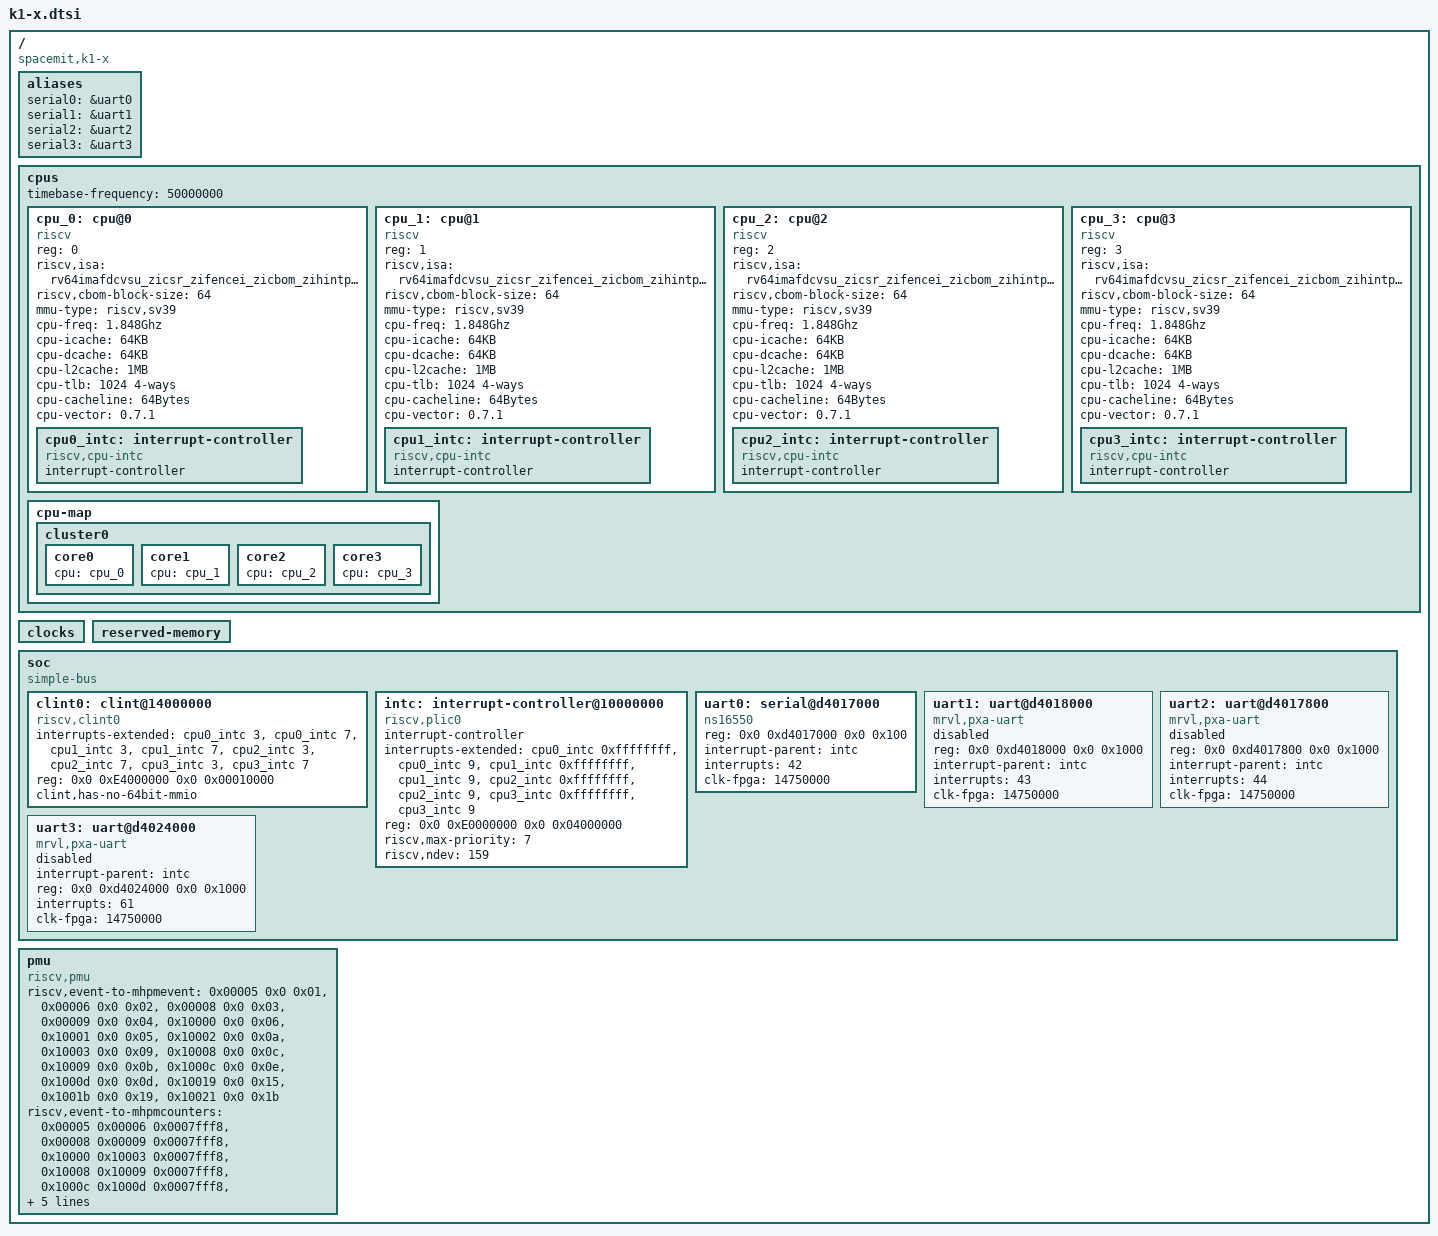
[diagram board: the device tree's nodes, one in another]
// SPDX-License-Identifier: (GPL-2.0 OR MIT)
/* Copyright (c) 2022 Spacemit, Inc */

/dts-v1/;


/ {
	compatible = "spacemit,k1-x", "riscv";
	#address-cells = <2>;
	#size-cells = <2>;

	aliases {
		serial0 = &uart0;
		serial1 = &uart1;
		serial2 = &uart2;
		serial3 = &uart3;
	};

	cpus: cpus {
		#address-cells = <1>;
		#size-cells = <0>;
		timebase-frequency = <50000000>;
		cpu_0: cpu@0 {
			device_type = "cpu";
			reg = <0>;
			status = "okay";
			compatible = "riscv";
			riscv,isa = "rv64imafdcvsu_zicsr_zifencei_zicbom_zihintpause_zba_zbb_zbc_zbs_svpbmt";
			riscv,cbom-block-size = <64>;
			mmu-type = "riscv,sv39";
			cpu-freq = "1.848Ghz";
			cpu-icache = "64KB";
			cpu-dcache = "64KB";
			cpu-l2cache = "1MB";
			cpu-tlb = "1024 4-ways";
			cpu-cacheline = "64Bytes";
			cpu-vector = "0.7.1";

			cpu0_intc: interrupt-controller {
				#interrupt-cells = <1>;
				compatible = "riscv,cpu-intc";
				interrupt-controller;
			};
		};
		cpu_1: cpu@1 {
			device_type = "cpu";
			reg = <1>;
			status = "okay";
			compatible = "riscv";
			riscv,isa = "rv64imafdcvsu_zicsr_zifencei_zicbom_zihintpause_zba_zbb_zbc_zbs_svpbmt";
			riscv,cbom-block-size = <64>;
			mmu-type = "riscv,sv39";
			cpu-freq = "1.848Ghz";
			cpu-icache = "64KB";
			cpu-dcache = "64KB";
			cpu-l2cache = "1MB";
			cpu-tlb = "1024 4-ways";
			cpu-cacheline = "64Bytes";
			cpu-vector = "0.7.1";

			cpu1_intc: interrupt-controller {
				#interrupt-cells = <1>;
				compatible = "riscv,cpu-intc";
				interrupt-controller;
			};
		};
		cpu_2: cpu@2 {
			device_type = "cpu";
			reg = <2>;
			status = "okay";
			compatible = "riscv";
			riscv,isa = "rv64imafdcvsu_zicsr_zifencei_zicbom_zihintpause_zba_zbb_zbc_zbs_svpbmt";
			riscv,cbom-block-size = <64>;
			mmu-type = "riscv,sv39";
			cpu-freq = "1.848Ghz";
			cpu-icache = "64KB";
			cpu-dcache = "64KB";
			cpu-l2cache = "1MB";
			cpu-tlb = "1024 4-ways";
			cpu-cacheline = "64Bytes";
			cpu-vector = "0.7.1";

			cpu2_intc: interrupt-controller {
				#interrupt-cells = <1>;
				compatible = "riscv,cpu-intc";
				interrupt-controller;
			};
		};
		cpu_3: cpu@3 {
			device_type = "cpu";
			reg = <3>;
			status = "okay";
			compatible = "riscv";
			riscv,isa = "rv64imafdcvsu_zicsr_zifencei_zicbom_zihintpause_zba_zbb_zbc_zbs_svpbmt";
			riscv,cbom-block-size = <64>;
			mmu-type = "riscv,sv39";
			cpu-freq = "1.848Ghz";
			cpu-icache = "64KB";
			cpu-dcache = "64KB";
			cpu-l2cache = "1MB";
			cpu-tlb = "1024 4-ways";
			cpu-cacheline = "64Bytes";
			cpu-vector = "0.7.1";

			cpu3_intc: interrupt-controller {
				#interrupt-cells = <1>;
				compatible = "riscv,cpu-intc";
				interrupt-controller;
			};
		};

		cpu-map {
			cluster0 {
				core0 {
					cpu = <&cpu_0>;
				};

				core1 {
					cpu = <&cpu_1>;
				};
				core2 {
					cpu = <&cpu_2>;
				};

				core3 {
					cpu = <&cpu_3>;
				};
			};
		};
	};

	clocks {
		#address-cells = <0x2>;
		#size-cells = <0x2>;
		ranges;
	};

	reserved-memory {
		#address-cells = <2>;
		#size-cells = <2>;
		ranges;
	};

	soc {
		compatible = "simple-bus";
		#address-cells = <2>;
		#size-cells = <2>;
		ranges;

		clint0: clint@14000000 {
			compatible = "riscv,clint0";
			interrupts-extended = <
				&cpu0_intc  3 &cpu0_intc  7
				&cpu1_intc  3 &cpu1_intc  7
				&cpu2_intc  3 &cpu2_intc  7
				&cpu3_intc  3 &cpu3_intc  7
			>;
			reg = <0x0 0xE4000000 0x0 0x00010000>;
			clint,has-no-64bit-mmio;
		};

		intc: interrupt-controller@10000000 {
			#interrupt-cells = <1>;
			compatible = "riscv,plic0";
			interrupt-controller;
			interrupts-extended = <
				&cpu0_intc 0xffffffff &cpu0_intc 9
				&cpu1_intc 0xffffffff &cpu1_intc 9
				&cpu2_intc 0xffffffff &cpu2_intc 9
				&cpu3_intc 0xffffffff &cpu3_intc 9
			>;
			reg = <0x0 0xE0000000 0x0 0x04000000>;
			reg-names = "control";
			riscv,max-priority = <7>;
			riscv,ndev = <159>;
		};

		uart0: serial@d4017000 {
			compatible = "ns16550";
			reg = <0x0 0xd4017000 0x0 0x100>;
			interrupt-parent = <&intc>;
			interrupts = <42>;
			/*
			dmas = <&pdma0 AP_UART1_RX 1
				&pdma0 AP_UART1_TX 1>;
			dma-names = "rx", "tx";
			clocks = <&soc_clocks CLK_UART1>;
			*/
			clk-fpga = <14750000>;
			/*
			lpm-qos = <PM_QOS_CPUIDLE_BLOCK_AXI>;
			edge-wakeup-pin = <54>;
			*/
			status = "ok";
		};

		uart1: uart@d4018000 {
			compatible = "mrvl,pxa-uart";
			reg = <0x0 0xd4018000 0x0 0x1000>;
			interrupt-parent = <&intc>;
			interrupts = <43>;
			/*
			dmas = <&pdma0 AP_UART2_RX 1
				&pdma0 AP_UART2_TX 1>;
			dma-names = "rx", "tx";
			clocks = <&soc_clocks CLK_UART2>;
			*/

			clk-fpga = <14750000>;
			/*
			lpm-qos = <PM_QOS_CPUIDLE_BLOCK_AXI>;
			*/
			status = "disabled";
		};

		uart2: uart@d4017800 {
			compatible = "mrvl,pxa-uart";
			reg = <0x0 0xd4017800 0x0 0x1000>;
			interrupt-parent = <&intc>;
			interrupts = <44>;
			/*
			dmas = <&pdma0 AP_UART3_RX 1
				&pdma0 AP_UART3_TX 1>;
			dma-names = "rx", "tx";
			clocks = <&soc_clocks CLK_UART3>;
			*/
			clk-fpga = <14750000>;
			/*
			lpm-qos = <PM_QOS_CPUIDLE_BLOCK_AXI>;
			*/
			status = "disabled";
		};

		uart3: uart@d4024000 {
			compatible = "mrvl,pxa-uart";
			interrupt-parent = <&intc>;
			reg = <0x0 0xd4024000 0x0 0x1000>;
			interrupts = <61>;
			/*
			dmas = <&pdma0 AP_UART4_RX 1
				&pdma0 AP_UART4_TX 1>;
			dma-names = "rx", "tx";
			clocks = <&soc_clocks CLK_UART4>;
			*/
			clk-fpga = <14750000>;
			/*
			lpm-qos = <PM_QOS_CPUIDLE_BLOCK_AXI>;
			*/
			status = "disabled";
		};
	};

	pmu {
		compatible = "riscv,pmu";

		riscv,event-to-mhpmevent =
			/* BRANCH_INSTRUCTIONS */
			<0x00005 0x0 0x01>,
			/* BRANCH_MISSES */
			<0x00006 0x0 0x02>,
			/* STALLED_CYCLES_FRONTEND */
			<0x00008 0x0 0x03>,
			/* STALLED_CYCLES_BACKEND */
			<0x00009 0x0 0x04>,
			/* L1D_READ_ACCESS */
			<0x10000 0x0 0x06>,
			/* L1D_READ_MISS */
			<0x10001 0x0 0x05>,
			/* L1D_WRITE_ACCESS */
			<0x10002 0x0 0x0a>,
			/* L1D_WRITE_MISS */
			<0x10003 0x0 0x09>,
			/* L1I_READ_ACCESS */
			<0x10008 0x0 0x0c>,
			/* L1I_READ_MISS */
			<0x10009 0x0 0x0b>,
			/* L1I_PREFETCH_ACCESS */
			<0x1000c 0x0 0x0e>,
			/* L1I_PREFETCH_MISS */
			<0x1000d 0x0 0x0d>,
			/* DTLB_READ_MISS */
			<0x10019 0x0 0x15>,
			/* DTLB_WRITE_MISS */
			<0x1001b 0x0 0x19>,
			/* ITLB_READ_MISS */
			<0x10021 0x0 0x1b>;

		/* 16 valid counters: mhpmcounter3 ~ mhpmcounter18 */
		riscv,event-to-mhpmcounters =
			<0x00005 0x00006 0x0007fff8>,
			<0x00008 0x00009 0x0007fff8>,
			<0x10000 0x10003 0x0007fff8>,
			<0x10008 0x10009 0x0007fff8>,
			<0x1000c 0x1000d 0x0007fff8>,
			<0x10019 0x10019 0x0007fff8>,
			<0x1001b 0x1001b 0x0007fff8>,
			<0x10021 0x10021 0x0007fff8>;

		riscv,raw-event-to-mhpmcounters =
			/*
			 * For convenience, we treat 0x1~0xff as valid indexes,
			 * but actually in hardware the valid indexes are 0x1~0xbd.
			 */
			<0x0 0x0 0xffffffff 0xffffff00 0x0007fff8>;
	};
};

